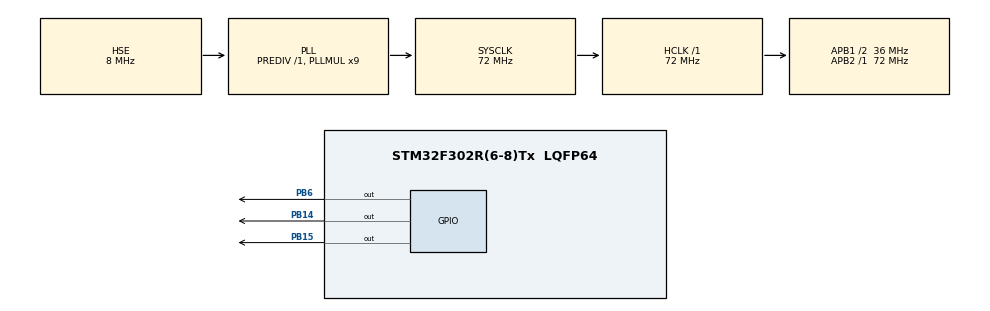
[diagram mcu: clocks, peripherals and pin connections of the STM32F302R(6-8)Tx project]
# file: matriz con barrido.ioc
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Mcu.Family=STM32F3
Mcu.Name=STM32F302R(6-8)Tx
Mcu.Package=LQFP64
NVIC.PriorityGroup=NVIC_PRIORITYGROUP_0
PA13.Mode=Serial_Wire
PA13.Signal=SYS_JTMS-SWDIO
PA14.Mode=Serial_Wire
PA14.Signal=SYS_JTCK-SWCLK
PB14.Signal=GPIO_Output
PB15.Signal=GPIO_Output
PB6.Signal=GPIO_Output
PF0-OSC_IN.Mode=HSE-External-Oscillator
PF0-OSC_IN.Signal=RCC_OSC_IN
PF1-OSC_OUT.Mode=HSE-External-Oscillator
PF1-OSC_OUT.Signal=RCC_OSC_OUT
ProjectManager.HeapSize=0x200
ProjectManager.StackSize=0x400
ProjectManager.TargetToolchain=STM32CubeIDE
RCC.AHBFreq_Value=72000000
RCC.APB1CLKDivider=RCC_HCLK_DIV2
RCC.APB1Freq_Value=36000000
RCC.APB1TimFreq_Value=72000000
RCC.APB2Freq_Value=72000000
RCC.APB2TimFreq_Value=72000000
RCC.CortexFreq_Value=72000000
RCC.HCLKFreq_Value=72000000
RCC.HSE_VALUE=8000000
RCC.HSI_VALUE=8000000
RCC.PLLM=8
RCC.PLLMUL=RCC_PLL_MUL9
RCC.PLLN=336
RCC.PLLP=RCC_PLLP_DIV4
RCC.PLLQ=7
RCC.PLLSourceVirtual=RCC_PLLSOURCE_HSE
RCC.SYSCLKFreq_VALUE=72000000
RCC.SYSCLKSourceVirtual=RCC_SYSCLKSOURCE_PLLCLK
RCC.USBFreq_Value=72000000
board=NUCLEO-F302R8

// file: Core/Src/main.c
/* USER CODE BEGIN Header */
/**
  ******************************************************************************
  * @file           : main.c
  * @brief          : Main program body
  ******************************************************************************
  * @attention
  *
  * Copyright (c) 2023 STMicroelectronics.
  * All rights reserved.
  *
  * This software is licensed under terms that can be found in the LICENSE file
  * in the root directory of this software component.
  * If no LICENSE file comes with this software, it is provided AS-IS.
  *
  ******************************************************************************
  */
/* USER CODE END Header */
#include "main.h"

/* USER CODE BEGIN Includes */
#include "max_matrix_stm32.h"
/* USER CODE END Includes */

void SystemClock_Config(void);
static void MX_GPIO_Init(void);

int main(void)
{

  /* MCU Configuration--------------------------------------------------------*/

  /* Reset of all peripherals, Initializes the Flash interface and the Systick. */
  HAL_Init();

  /* Configure the system clock */
  SystemClock_Config();

  /* Initialize all configured peripherals */
  MX_GPIO_Init();
  /* USER CODE BEGIN 2 */
  max_init (0x03);

  //	write_char ('A',4);  // write 'A' on 4th display
  	//write_char ('2',3);  // write '2' on 3rd display
  	//write_char (3,2);  // print heart on 2nd display
  	//write_char (0b01111111,1);  // write 'm'on st display

  /* USER CODE END 2 */

  /* Infinite loop */
  while (1)
  {

    /* USER CODE BEGIN 3 */

	 //scroll_char (0b01111111  , 200, right); // right - left
	  		scroll_string ((uint8_t *) "Angel Gabrir 2021-0311 "  , 150, left);

  }
  /* USER CODE END 3 */
}

void SystemClock_Config(void)
{
  RCC_OscInitTypeDef RCC_OscInitStruct = {0};
  RCC_ClkInitTypeDef RCC_ClkInitStruct = {0};

  /** Initializes the RCC Oscillators according to the specified parameters
  * in the RCC_OscInitTypeDef structure.
  */
  RCC_OscInitStruct.OscillatorType = RCC_OSCILLATORTYPE_HSE;
  RCC_OscInitStruct.HSEState = RCC_HSE_ON;
  RCC_OscInitStruct.HSEPredivValue = RCC_HSE_PREDIV_DIV1;
  RCC_OscInitStruct.HSIState = RCC_HSI_ON;
  RCC_OscInitStruct.PLL.PLLState = RCC_PLL_ON;
  RCC_OscInitStruct.PLL.PLLSource = RCC_PLLSOURCE_HSE;
  RCC_OscInitStruct.PLL.PLLMUL = RCC_PLL_MUL9;
  if (HAL_RCC_OscConfig(&RCC_OscInitStruct) != HAL_OK)
  {
    Error_Handler();
  }

  /** Initializes the CPU, AHB and APB buses clocks
  */
  RCC_ClkInitStruct.ClockType = RCC_CLOCKTYPE_HCLK|RCC_CLOCKTYPE_SYSCLK
                              |RCC_CLOCKTYPE_PCLK1|RCC_CLOCKTYPE_PCLK2;
  RCC_ClkInitStruct.SYSCLKSource = RCC_SYSCLKSOURCE_PLLCLK;
  RCC_ClkInitStruct.AHBCLKDivider = RCC_SYSCLK_DIV1;
  RCC_ClkInitStruct.APB1CLKDivider = RCC_HCLK_DIV2;
  RCC_ClkInitStruct.APB2CLKDivider = RCC_HCLK_DIV1;

  if (HAL_RCC_ClockConfig(&RCC_ClkInitStruct, FLASH_LATENCY_2) != HAL_OK)
  {
    Error_Handler();
  }
}

static void MX_GPIO_Init(void)
{
  GPIO_InitTypeDef GPIO_InitStruct = {0};

  /* GPIO Ports Clock Enable */
  __HAL_RCC_GPIOF_CLK_ENABLE();
  __HAL_RCC_GPIOB_CLK_ENABLE();
  __HAL_RCC_GPIOA_CLK_ENABLE();

  /*Configure GPIO pin Output Level */
  HAL_GPIO_WritePin(GPIOB, GPIO_PIN_14|GPIO_PIN_15|GPIO_PIN_6, GPIO_PIN_RESET);

  /*Configure GPIO pins : PB14 PB15 PB6 */
  GPIO_InitStruct.Pin = GPIO_PIN_14|GPIO_PIN_15|GPIO_PIN_6;
  GPIO_InitStruct.Mode = GPIO_MODE_OUTPUT_PP;
  GPIO_InitStruct.Pull = GPIO_NOPULL;
  GPIO_InitStruct.Speed = GPIO_SPEED_FREQ_LOW;
  HAL_GPIO_Init(GPIOB, &GPIO_InitStruct);

}

void Error_Handler(void)
{
  __disable_irq();
  while (1)
  {
  }
}
